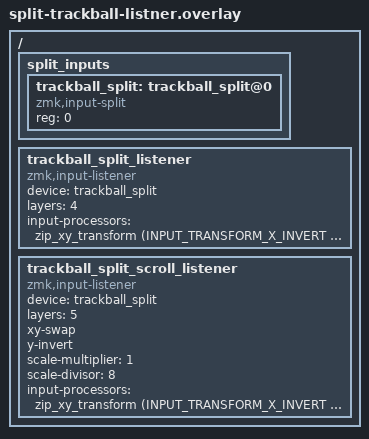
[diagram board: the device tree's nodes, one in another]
/{
    split_inputs {
        #address-cells = <1>;
        #size-cells = <0>;

        trackball_split: trackball_split@0 {
            compatible = "zmk,input-split";
            reg = <0>;
        };
    };

    trackball_split_listener: trackball_split_listener {
        compatible = "zmk,input-listener";
        device = <&trackball_split>;
        status = "okay";
        layers = <4>;
        input-processors = <&zip_xy_transform (INPUT_TRANSFORM_X_INVERT | INPUT_TRANSFORM_Y_INVERT)>;
     };
     
     trackball_split_scroll_listener: trackball_split_scroll_listener {
        compatible = "zmk,input-listener";
        device = <&trackball_split>;
        status = "okay";
        layers = <5>;
        xy-swap;
        y-invert;
        scale-multiplier = <1>;
        scale-divisor = <8>;
        input-processors = <&zip_xy_transform (INPUT_TRANSFORM_X_INVERT | INPUT_TRANSFORM_Y_INVERT)>;
     };
};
